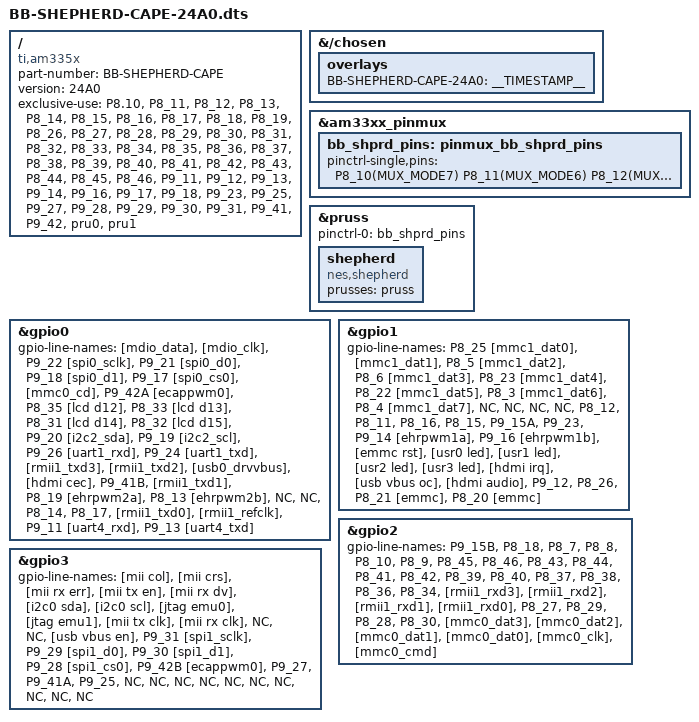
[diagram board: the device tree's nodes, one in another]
// for Hardware of Cape v2.4 a/b/c
/dts-v1/;
/plugin/;
#include "am335x_pinctrl.h"

// TODO: overlays have been simplified! https://github.com/beagleboard/bb.org-overlays/commit/187c1354a3f6466fa90eca152910c6c0b42250aa
/*
// future-reference, gpio.h contains: BONE_P8_03, etc
#include <dt-bindings/gpio/gpio.h>
// future-reference, omap.h contains: MUX_MODE#, PULL_UP, INPUT_EN, AM33XX_IOPAD, AM33XX_PADCONF, etc
#include <dt-bindings/pinctrl/omap.h>
*/


/ {
    compatible = "ti,am335x", "ti,am335x-bone", "ti,am335x-bone-black", "ti,am335x-bone-green", "seeed,am335x-bone-green-eco";

    part-number = "BB-SHEPHERD-CAPE";
    version = "24A0";

    /* This overlay uses the following resources */
    exclusive-use =

        "P8.10", /*     WD ACK */
        "P8_11", /*     pru0_dbg_Led1 */
        "P8_12", /*     pru0_dbg_Led0 */
        "P8_13", /*     EN_Shepherd */
        "P8_14", /*     target_GPIO0 */
        "P8_15", /* 	target_GPIO3 */
        "P8_16", /* 	target_GPIO2 */
        "P8_17", /* 	target_GPIO1 */
        "P8_18", /* 	BTN Sense */
        "P8_19", /* 	BTN Led */

        "P8_26", /* 	target_GPIO4 */
        "P8_27", /* 	pru1_target_uart-tx */
        "P8_28", /* 	pru1_dbg_Led0 */
        "P8_29", /* 	pru1_target_batOK */
        "P8_30", /* 	pru1_dbg_Led1 */
        "P8_31", /* 	IO-Dir Program1 TDIO */
        "P8_32", /* 	IO-Dir Program2 TMS */
        "P8_33", /* 	target_swd2_io */
        "P8_34", /* 	target_GPIO6 */
        "P8_35", /*     target_swd2_CLK */
        "P8_36", /*     target_GPIO5 */
        "P8_37", /*     IO_DIR_GPIO 0to3 */
        "P8_38", /*     IO_DIR_UART-TX */
        "P8_39", /* 	pru1_target_gpio6 */
        "P8_40", /* 	pru1_target_uart-tx */
        "P8_41", /* 	pru1_target_gpio4 */
        "P8_42", /* 	pru1_target_gpio5 */
        "P8_43", /* 	pru1_target_gpio2 */
        "P8_44", /* 	pru1_target_gpio3 */
        "P8_45", /* 	pru1_target_gpio0 */
        "P8_46", /* 	pru1_target_gpio1 */

        "P9_11", /* 	target_io_SEL */
        "P9_12", /* 	target_io_EN */
        "P9_13", /* 	target_Pwr_SEL */
        "P9_14", /*     EN_Recorder */

        "P9_16", /*     EN_Emulator */
        "P9_17", /* 	target_swd1_clk */
        "P9_18", /* 	target_swd1_io */

        "P9_23", /* 	Mem_WP */

        "P9_25", /* 	pru0 SPI_CS_ADC2_REC */

        "P9_27", /* 	pru0 SPI_CS_DAC_REC */
        "P9_28", /* 	pru0 SPI_CS_DAC_EMU */
        "P9_29", /* 	pru0 SPI_MOSI */
        "P9_30", /* 	pru0 SPI_MISO */
        "P9_31", /* 	pru0 SPI_SCK */

        "P9_41", /* 	pru0 SPI_CS_ADC1_REC */
        "P9_42", /* 	pru0 SPI_CS_ADC_EMU */

        /* Realtime Units */
        "pru0",
        "pru1";

        // additional shepherd-pins (there are covered by bb-overlays)
        // GPS,
        //"P8.07", /*  GPS PPS */
        //"P8.08", /*  GPS nReset */
        //"P8.09", /*  GPS Safeboot */
        //"P9_21", /*  GPS UART2TX */  // UART2
        //"P9_22", /*  GPS UART2RX */

        // EEPROM
        //"P9_19", /*  Mem_SCL */      // I2C2
        //"P9_20", /*  Mem_SDA */

        // Target UART - TODO: only active for TESTs
        //"P9_24", /*  target_uart_tx */ // UART1
        //"P9_26", /*  target_uart_rx */
};

/* Check Table 9-60 in am335x TRM */

/* Helper to show loaded overlays under: /proc/device-tree/chosen/overlays/  */
// &{/chosen/overlays} { -> should, but does not work?
&{/chosen} {
	overlays {
	BB-SHEPHERD-CAPE-24A0 = __TIMESTAMP__;
	};
};

&am33xx_pinmux {
    bb_shprd_pins: pinmux_bb_shprd_pins {
        pinctrl-single,pins = <

            P8_10(MUX_MODE7)                // gpio2[4]
            P8_11(MUX_MODE6)                // pr1_pru0_pru_r30_15
            P8_12(MUX_MODE6)                // pr1_pru0_pru_r30_14
            P8_13(MUX_MODE7)                // gpio0[23]
            P8_14(MUX_MODE7 | RX_ACTIVE)    // gpio0[26]
            P8_15(MUX_MODE7 | RX_ACTIVE)    // gpio1[15]
            P8_16(MUX_MODE7 | RX_ACTIVE)    // gpio1[14]
            P8_17(MUX_MODE7 | RX_ACTIVE)    // gpio0[27]
            P8_18(MUX_MODE7 | RX_ACTIVE)    // gpio2[1]
            P8_19(MUX_MODE7)                // gpio0[22]

            P8_26(MUX_MODE7 | RX_ACTIVE)    // gpio1[29]
            P8_27(MUX_MODE6 | RX_ACTIVE)    // pr1_pru1_pru_r31_8
            P8_28(MUX_MODE5)                // pr1_pru1_pru_r30_10
            P8_29(MUX_MODE5)                // pr1_pru1_pru_r30_9   BATOK, only output
            P8_30(MUX_MODE5)                // pr1_pru1_pru_r30_11

            P8_31(MUX_MODE7)                // gpio0[10]
            P8_32(MUX_MODE7)                // gpio0[11]
            P8_33(MUX_MODE7 | RX_ACTIVE)    // gpio0[9]
            P8_34(MUX_MODE7 | RX_ACTIVE)    // gpio2[17]
            P8_35(MUX_MODE7 | RX_ACTIVE)    // gpio0[8], rx not needed for clock, just debug
            P8_36(MUX_MODE7 | RX_ACTIVE)    // gpio2[16]
            P8_37(MUX_MODE7)                // gpio2[14]
            P8_38(MUX_MODE7)                // gpio2[15]

            P8_39(MUX_MODE6 | RX_ACTIVE)    // pr1_pru1_pru_r31_6
            P8_40(MUX_MODE6 | RX_ACTIVE)    // pr1_pru1_pru_r31_7
            P8_41(MUX_MODE6 | RX_ACTIVE)    // pr1_pru1_pru_r31_4
            P8_42(MUX_MODE6 | RX_ACTIVE)    // pr1_pru1_pru_r31_5
            P8_43(MUX_MODE6 | RX_ACTIVE)    // pr1_pru1_pru_r31_2
            P8_44(MUX_MODE6 | RX_ACTIVE)    // pr1_pru1_pru_r31_3
            P8_45(MUX_MODE6 | RX_ACTIVE)    // pr1_pru1_pru_r31_0
            P8_46(MUX_MODE6 | RX_ACTIVE)    // pr1_pru1_pru_r31_1

            P9_11(MUX_MODE7)                // gpio0[30]
            P9_12(MUX_MODE7)                // gpio1[28]
            P9_13(MUX_MODE7)                // gpio0[31]

            P9_14(MUX_MODE7)                // gpio1[18], 50
            P9_16(MUX_MODE7)                // gpio1[19], 51

            P9_17(MUX_MODE7 | RX_ACTIVE)    // gpio0[5], swd_clk, rx not needed for clock, just debug
            P9_18(MUX_MODE7 | RX_ACTIVE)    // gpio0[4], swd_io

            P9_23(MUX_MODE7)                // gpio1[17]

            P9_25(MUX_MODE5)                // pr1_pru0_pru_r30_7

            P9_27(MUX_MODE5)                // pr1_pru0_pru_r30_5
            P9_28(MUX_MODE5)                // pr1_pru0_pru_r30_3
            P9_29(MUX_MODE5)                // pr1_pru0_pru_r30_1
            P9_30(MUX_MODE6 | RX_ACTIVE)    // pr1_pru0_pru_r31_2
            P9_31(MUX_MODE5)                // pr1_pru0_pru_r30_0

            P9_41B(MUX_MODE5)               // pr1_pru0_pru_r30_6
            P9_42B(MUX_MODE5)               // pr1_pru0_pru_r30_4

            // just for tests, does not hinder uart-module from loading
            //P9_24(MUX_MODE7 | RX_ACTIVE)    // usually uart1
            //P9_26(MUX_MODE7 | RX_ACTIVE)    // usually uart1

        >;
    };
};

&pruss {
    status = "okay";
    pinctrl-names = "default";
    pinctrl-0 = <&bb_shprd_pins>;
    //memory-region = <&pru_dma_pool>;
    shepherd {
        compatible = "nes,shepherd";
        prusses = <&pruss>;
    };
};

/*
// also needed is "memory-region =" in fragment@2
// TODO: PRU carves out its own memory, so it won't use this (yet)
&{/} {
    reserved-memory {
        #address-cells = <0x01>;
        #size-cells = <0x01>;
        ranges;

        pru_dma_pool: pru-dma-pool@9C200000 {
            compatible = "shared-dma-pool";
            //reg = <0x9C200000 0x3000000>; // 50 MB
            reg = <0x9C000000 0x02dc6524>; // 48 MB
            no-map;
            status = "okay";
        };
    };
};
*/

// Code below is copied from https://github.com/beagleboard/BeagleBoard-DeviceTrees/blob/v7.3.x/src/arm/ti/omap/am335x-bonegreen.dts
// Missing for BBG Eco
// TODO: try disabling pm/ocmc this way to get the full cache

&gpio0 {
	gpio-line-names =
		"[mdio_data]",
		"[mdio_clk]",
		"P9_22 [spi0_sclk]",
		"P9_21 [spi0_d0]",
		"P9_18 [spi0_d1]",
		"P9_17 [spi0_cs0]",
		"[mmc0_cd]",
		"P9_42A [ecappwm0]",
		"P8_35 [lcd d12]",
		"P8_33 [lcd d13]",
		"P8_31 [lcd d14]",
		"P8_32 [lcd d15]",
		"P9_20 [i2c2_sda]",
		"P9_19 [i2c2_scl]",
		"P9_26 [uart1_rxd]",
		"P9_24 [uart1_txd]",
		"[rmii1_txd3]",
		"[rmii1_txd2]",
		"[usb0_drvvbus]",
		"[hdmi cec]",
		"P9_41B",
		"[rmii1_txd1]",
		"P8_19 [ehrpwm2a]",
		"P8_13 [ehrpwm2b]",
		"NC",
		"NC",
		"P8_14",
		"P8_17",
		"[rmii1_txd0]",
		"[rmii1_refclk]",
		"P9_11 [uart4_rxd]",
		"P9_13 [uart4_txd]";
};

&gpio1 {
	gpio-line-names =
		"P8_25 [mmc1_dat0]",
		"[mmc1_dat1]",
		"P8_5 [mmc1_dat2]",
		"P8_6 [mmc1_dat3]",
		"P8_23 [mmc1_dat4]",
		"P8_22 [mmc1_dat5]",
		"P8_3 [mmc1_dat6]",
		"P8_4 [mmc1_dat7]",
		"NC",
		"NC",
		"NC",
		"NC",
		"P8_12",
		"P8_11",
		"P8_16",
		"P8_15",
		"P9_15A",
		"P9_23",
		"P9_14 [ehrpwm1a]",
		"P9_16 [ehrpwm1b]",
		"[emmc rst]",
		"[usr0 led]",
		"[usr1 led]",
		"[usr2 led]",
		"[usr3 led]",
		"[hdmi irq]",
		"[usb vbus oc]",
		"[hdmi audio]",
		"P9_12",
		"P8_26",
		"P8_21 [emmc]",
		"P8_20 [emmc]";
};

&gpio2 {
	gpio-line-names =
		"P9_15B",
		"P8_18",
		"P8_7",
		"P8_8",
		"P8_10",
		"P8_9",
		"P8_45",
		"P8_46",
		"P8_43",
		"P8_44",
		"P8_41",
		"P8_42",
		"P8_39",
		"P8_40",
		"P8_37",
		"P8_38",
		"P8_36",
		"P8_34",
		"[rmii1_rxd3]",
		"[rmii1_rxd2]",
		"[rmii1_rxd1]",
		"[rmii1_rxd0]",
		"P8_27",
		"P8_29",
		"P8_28",
		"P8_30",
		"[mmc0_dat3]",
		"[mmc0_dat2]",
		"[mmc0_dat1]",
		"[mmc0_dat0]",
		"[mmc0_clk]",
		"[mmc0_cmd]";
};

&gpio3 {
	gpio-line-names =
		"[mii col]",
		"[mii crs]",
		"[mii rx err]",
		"[mii tx en]",
		"[mii rx dv]",
		"[i2c0 sda]",
		"[i2c0 scl]",
		"[jtag emu0]",
		"[jtag emu1]",
		"[mii tx clk]",
		"[mii rx clk]",
		"NC",
		"NC",
		"[usb vbus en]",
		"P9_31 [spi1_sclk]",
		"P9_29 [spi1_d0]",
		"P9_30 [spi1_d1]",
		"P9_28 [spi1_cs0]",
		"P9_42B [ecappwm0]",
		"P9_27",
		"P9_41A",
		"P9_25",
		"NC",
		"NC",
		"NC",
		"NC",
		"NC",
		"NC",
		"NC",
		"NC",
		"NC",
		"NC";
};
